# SAMA7D65D2GN8 register map
Vendor: Microchip Technology; Series: SAMA7D6; File version: 0
Registers are 32-bit, read-write, reset 0x0 unless marked. A register's access mark holds for its fields unless they carry their own. Offsets are from the block's base; [hi:lo] are bit positions; lines under a group give offsets from that group; {n}, {i} and the like mark numbered series; 'fields as' and 'values as' point back to an identical list.

## I2SMCC0 — Inter-IC Sound Multi Channel Controller
Base 0xE2814000; register names take the prefix I2SMCC_
Same registers: I2SMCC1 0xE2818000
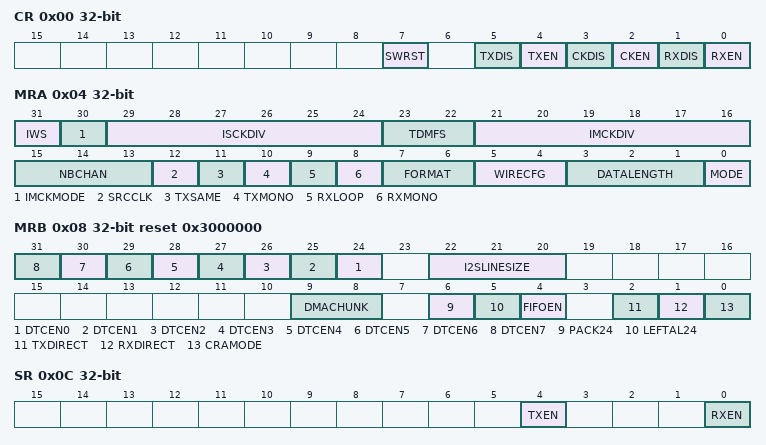
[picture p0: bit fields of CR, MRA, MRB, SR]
0x00 CR wo — Control Register
  [7] SWRST — Software Reset
    0=No effect; 1=Resets all the registers in the I2SMCC. The I2SMCC is disabled after the reset.
  [5] TXDIS — Transmitter Disable
    0=No effect; 1=Disables the I2SMCC transmitter. Bit I2SMCC_SR.TXEN is cleared when the Transmitter is stopped.
  [4] TXEN — Transmitter Enable
    0=No effect; 1=Enables the I2SMCC transmitter, if TXDIS is not '1'. Bit I2SMCC_SR.TXEN is set when the Transmitter is started.
  [3] CKDIS — Clocks Disable
    0=No effect; 1=Disables the I2SMCC clock generation
  [2] CKEN — Clocks Enable
    0=No effect; 1=Enables the I2SMCC clock generation, if CKDIS is not '1'
  [1] RXDIS — Receiver Disable
    0=No effect; 1=Disables the I2SMCC receiver. Bit I2SMCC_SR.RXEN is cleared when the receiver is stopped.
  [0] RXEN — Receiver Enable
    0=No effect; 1=Enables the I2SMCC receiver, if RXDIS is not '1'. Bit I2SMCC_SR.RXEN is set when the receiver is activated.
0x04 MRA — Mode Register A
  [31] IWS — I2SMCC_WS Slot Length
    0=I2SMCC_WS slot is 32 bits long for DATALENGTH = 18/20/24 bits; 1=I2SMCC_WS slot is 24 bits long for DATALENGTH = 18/20/24 bits
  [30] IMCKMODE — Host Clock Mode
    0=No host clock generated; 1=Host clock generated
  [29:24] ISCKDIV — Selected Clock to I2SMCC Serial Clock Ratio
  [23:22] TDMFS — TDM Frame Synchronization
    0=SLOT (I2SMCC_WS pulse is high for one time slot at beginning of frame.); 1=HALF (I2SMCC_WS pulse is high for half the time slots at beginning of frame.); 2=BIT (I2SMCC_WS pulse is high for one bit period at beginning of frame, i.e., one I2SMCC_CK period.)
  [21:16] IMCKDIV — Selected Clock to I2SMCC Host Clock Ratio
  [15:13] NBCHAN — Number of TDM Channels-1
  [12] SRCCLK — Source Clock Selection
    0=The Peripheral clock is selected as source clock for I2SMCC_MCK/WS/CK pins; 1=The PMC.GCLKx clock is selected as source clock (I2SMCC_MCK/WS/CK rate can be independent of system bus clock)
  [11] TXSAME — Transmit Data when Underrun
    0='0' is transmitted when underrun; 1=Previous sample transmitted when underrun
  [10] TXMONO — Transmit Mono
    0=Stereo; 1=Mono, with left audio samples duplicated to right audio channel by the I2SMCC
  [9] RXLOOP — Loop-back Test Mode
    0=Normal mode; 1=I2SMCC_DOUT outputs of I2SMCC are internally connected to I2SMCC_DIN inputs
  [8] RXMONO — Receive Mono
    values as TXMONO
  [7:6] FORMAT — Data Format
    0=I2S (I2S format, stereo with I2SMCC_WS low for left channel, and MSB of sample starting one I2SMCC_CK period after I2SMCC_WS edge.); 1=LJ (Left-justified format, stereo with I2SMCC_WS high for left channel, and MSB of sample starting on I2SMCC_WS edge.); 2=TDM (TDM format, with (NBCHAN + 1) channels, I2SMCC_WS high at beginning of first channel, and MSB of sample starting one I2SMCC_CK period after I2SMCC_WS edge.); 3=TDMLJ (TDM format, left-justified, with (NBCHAN + 1) channels, I2SMCC_WS high at beginning of first channel, and MSB of sample starting on I2SMCC_WS edge.)
  [5:4] WIRECFG — Wire Configuration
    0=I2S_1_TDM_0 (In I2S and LJ formats, I2SMCC_DIN0 and I2SMCC_DOUT0 are used to transmit and receive I2S frames. In TDM and TDMLJ formats, I2SMCC_DIN0 and I2SMCC_DOUT0 are used to transmit and receive TDM frames.); 1=I2S_2_TDM_1 (In I2S and LJ formats, I2SMCC_DIN[1:0] and I2SMCC_DOUT[1:0] are used to transmit and receive 2 I2S frames. In TDM and TDMLJ formats, I2SMCC_DIN1 and I2SMCC_DOUT1 are used to transmit and receive TDM frames.); 2=I2S_4_TDM_2 (In I2S and LJ formats, I2SMCC_DIN[3:0] and I2SMCC_DOUT[3:0] are used to transmit and receive 4 I2S frames. In TDM and TDMLJ formats, I2SMCC_DIN2 and I2SMCC_DOUT2 are used to transmit and receive TDM frames.); 3=TDM_3 (In I2S and LJ formats, reserved for future use, do not use. In TDM and TDMLJ formats, I2SMCC_DIN3 and I2SMCC_DOUT3 are used to transmit and receive TDM frames.)
  [3:1] DATALENGTH — Data Word Length
    0=32_BITS (Data length is set to 32 bits.); 1=24_BITS (Data length is set to 24 bits.); 2=20_BITS (Data length is set to 20 bits.); 3=18_BITS (Data length is set to 18 bits.); 4=16_BITS (Data length is set to 16 bits.); 5=16_BITS_COMPACT (Data length is set to 16-bit compact stereo. Left sample in bits [15:0] and right sample in bits [31:16] of same word.); 6=8_BITS (Data length is set to 8 bits.); 7=8_BITS_COMPACT (Data length is set to 8-bit compact stereo. Left sample in bits [7:0] and right sample in bits [15:8] of the same word.)
  [0] MODE — Inter-IC Sound Multi Channel Controller Mode
    0=SLAVE (Client mode. I2SMCC_CK and I2SMCC_WS pin inputs used as bit clock and word select/frame synchronization.); 1=MASTER (Host mode. Bit clock and word select/frame synchronization generated by I2SMCC from Peripheral Clock or GCLK if I2SMCC_MCK/WS/CK rates must be independent of system bus clock (See I2SMCC_MR.SRCCLK) and output to I2SMCC_CK and I2SMCC_WS pins. MCK is output as host clock on I2SMCC_MCK if I2SMCC_MRA.IMCKMODE is set.)
0x08 MRB reset 0x3000000 — Mode Register B
  [n+24] DTCEN{n} (n=0..7) — Direct Audio Transmit Channel {n} Enable
    0=The channel x from the direct audio stream is not transmitted on I2S line; 1=The channel x from the direct audio stream is transmitted on I2S line
  [22:20] I2SLINESIZE — I2S Transceiver Data Slot Size Selection
    0=DATALENGTH_DEFINED (The I2S data slot size is configured by I2SMCC_MRA.DATALENGTH and the software is forced to manage audio samples of the same size as the ones transfered on I2S line.); 1=32_BITS (The I2S data slot size is 32-bit. I2SMCC_MRA.DATALENGTH/IWS has no effect on I2S data slot size but defines the audio sample size managed at user interface level.); 2=32_24_BITS (The I2S data slot size is 24-bit or 32-bit. 32 or 24 bits depends on I2SMCC_MR.IWS. I2SMCC_MRA.DATALENGTH/IWS have no effect on I2S data slot size but define the audio sample size managed at user interface level.); 3=16_BITS (The I2S data slot size is 16-bit. I2SMCC_MRA.DATALENGTH/IWS have no effect on I2S data slot size but defines the audio sample size managed at user interface level.); 4=8_BITS (The I2S data slot size is 8-bit. I2SMCC_MRA.DATALENGTH/IWS have no effect on I2S data slot size but defines the audio sample size managed at user interface level.)
  [9:8] DMACHUNK — DMA Chunk Size
    0=1_WORD (A DMA transfer request is issued when at least 1 word is empty in the FIFO.); 1=2_WORDS (A DMA transfer request is issued when at least 2 words are empty in the FIFO. When PACK24=1, only 1-word chunks are allowed for the DMA transfer.); 2=4_WORDS (A DMA transfer request is issued when at least 4 words are empty in the FIFO. Limitations exist when operating in Mono or TDM. See Table 7-7 'TX DMA Chunk Configurations' and Table 7-8 'RX DMA Chunk Configurations'. When PACK24=1, only 1-word chunks are allowed for the DMA transfer.); 3=8_WORDS (A DMA transfer request is issued when at least 8 words are empty in the FIFO. Limitations exist when operating in Mono or TDM. See Table 7-7 'TX DMA Chunk Configurations' and Table 7-8 'RX DMA Chunk Configurations'. When PACK24=1, only 1-word chunks are allowed for the DMA transfer.)
  [6] PACK24 — Packed 24-bit Mode
    0=Each 24-bit audio sample is mapped into the 32-bit Holding register; 1=24-bit audio samples are compacted in the 32-bit Holding register to optimize data transfer in system bus and memory. The FIFO must be enabled (I2SMCC_MRB.FIFOEN = 1).
  [5] LEFTAL24 — Left Aligned 24-bit Data
    0=The 24-bit audio sample is right aligned in the 32-bit Holding register; 1=The 24-bit audio sample is left aligned in the 32-bit Holding register
  [4] FIFOEN — FIFO Enable
    0=The Receive and Transmit FIFOs are disabled; 1=The Receive and Transmit FIFOs are enabled. Transmit data can only be written through I2SMCC_THR. Receive data can only be read through I2SMCC_RHR.
  [2] TXDIRECT — Transmitter Direct Access Enable
    0=The I2SMCC_THR must be loaded by software or DMA to transfer audio sample on I2S line; 1=Audio Sample Rate Converter (ASRC) can directly transmit the converted audio samples on I2S line without software or DMA intervention. The FIFO must be enabled (I2SMCC_MRB.FIFOEN = 1).
  [1] RXDIRECT — Receiver Direct Access Enable
    0=The I2SMCC_RHR must be read by software or DMA to read audio samples from I2S line; 1=Audio Sample Rate Converter (ASRC) can be directly loaded with the audio samples recovered from I2S line without software or DMA intervention. The FIFO must be enabled (I2SMCC_MRB.FIFOEN = 1).
  [0] CRAMODE — Common Register Access Mode
    0=LEFT_FIRST (All enabled I2S left channels are filled first, then I2S right channels.); 1=REGULAR (An enabled I2S left channel is filled, then the corresponding right channel, until all channels are filled.)
0x0C SR ro — Status Register
  [4] TXEN — Transmitter Enabled
    0=Cleared when the transmitter is disabled, following a I2SMCC_CR.TXDIS or I2SMCC_CR.SWRST request; 1=Set when the transmitter is enabled, following a I2SMCC_CR.TXEN request
  [0] RXEN — Receiver Enabled
    0=Cleared when the receiver is disabled, following a RXDIS or SWRST request in I2SMCC_CR; 1=Set when the receiver is enabled, following a RXEN request in I2SMCC_CR
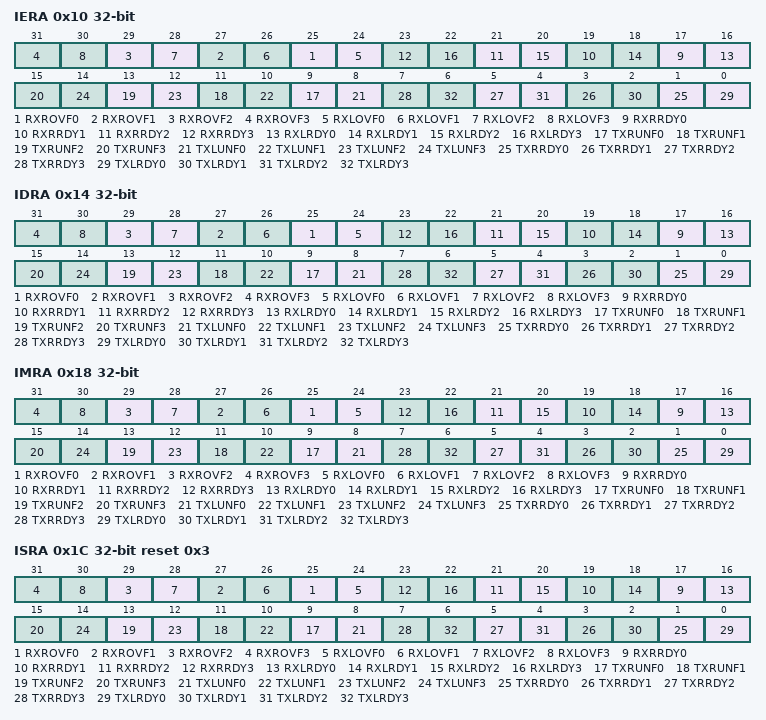
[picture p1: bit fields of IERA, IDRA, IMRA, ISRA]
0x10 IERA wo — Interrupt Enable Register A
  [2n+25] RXROVF{n} (n=0..3) — I2S Receive Right {n} or TDM Channel [2x]+1 Overrun Interrupt Enable
  [2n+24] RXLOVF{n} (n=0..3) — I2S Receive Left {n} or TDM Channel 2x Overrun Interrupt Enable
  [2n+17] RXRRDY{n} (n=0..3) — I2S Receive Right {n} or TDM Channel [2x]+1 Ready Interrupt Enable
  [2n+16] RXLRDY{n} (n=0..3) — I2S Receive Left {n} or TDM Channel 2x Ready Interrupt Enable
  [2n+9] TXRUNF{n} (n=0..3) — I2S Transmit Right {n} or TDM Channel [2x]+1 Underrun Interrupt Enable
  [2n+8] TXLUNF{n} (n=0..3) — I2S Transmit Left {n} or TDM Channel 2x Underrun Interrupt Enable
  [2n+1] TXRRDY{n} (n=0..3) — I2S Transmit Right {n} or TDM Channel [2x]+1 Ready Interrupt Enable
  [2n] TXLRDY{n} (n=0..3) — I2S Transmit Left {n} or TDM Channel 2x ReadyInterrupt Enable
0x14 IDRA wo — Interrupt Disable Register A
  [2n+25] RXROVF{n} (n=0..3) — I2S Receive Right {n} or TDM Channel [2x]+1 Overrun Interrupt Disable
  [2n+24] RXLOVF{n} (n=0..3) — I2S Receive Left {n} or TDM Channel 2x Overrun Interrupt Disable
  [2n+17] RXRRDY{n} (n=0..3) — I2S Receive Right {n} or TDM Channel [2x]+1 Ready Interrupt Disable
  [2n+16] RXLRDY{n} (n=0..3) — I2S Receive Left {n} or TDM Channel 2x Ready Interrupt Disable
  [2n+9] TXRUNF{n} (n=0..3) — I2S Transmit Right {n} or TDM Channel [2x]+1 Underrun Interrupt Disable
  [2n+8] TXLUNF{n} (n=0..3) — I2S Transmit Left {n} or TDM Channel 2x Underrun Interrupt Disable
  [2n+1] TXRRDY{n} (n=0..3) — I2S Transmit Right {n} or TDM Channel [2x]+1 Ready Interrupt Disable
  [2n] TXLRDY{n} (n=0..3) — I2S Transmit Left {n} or TDM Channel 2x ReadyInterrupt Disable
0x18 IMRA ro — Interrupt Mask Register A
  [2n+25] RXROVF{n} (n=0..3) — I2S Receive Right {n} or TDM Channel [2x]+1 Overrun Interrupt Mask
  [2n+24] RXLOVF{n} (n=0..3) — I2S Receive Left {n} or TDM Channel 2x Overrun Interrupt Mask
  [2n+17] RXRRDY{n} (n=0..3) — I2S Receive Right {n} or TDM Channel [2x]+1 Ready Interrupt Mask
  [2n+16] RXLRDY{n} (n=0..3) — I2S Receive Left {n} or TDM Channel 2x Ready Interrupt Mask
  [2n+9] TXRUNF{n} (n=0..3) — I2S Transmit Right {n} or TDM Channel [2x]+1 Underrun Interrupt Mask
  [2n+8] TXLUNF{n} (n=0..3) — I2S Transmit Left {n} or TDM Channel 2x Underrun Interrupt Mask
  [2n+1] TXRRDY{n} (n=0..3) — I2S Transmit Right {n} or TDM Channel [2x]+1 Ready Interrupt Mask
  [2n] TXLRDY{n} (n=0..3) — I2S Transmit Left {n} or TDM Channel 2x ReadyInterrupt Mask
0x1C ISRA ro reset 0x3 — Interrupt Status Register A
  [2n+25] RXROVF{n} (n=0..3) — I2S Receive Right {n} or TDM Channel [2x]+1 Overrun Flag (Cleared on read)
    0=Cleared when I2SMCC_ISRA is read; 1=Set when an overrun error occurs in either I2SMCC_RHRxR or I2SMCC_RHR
  [2n+24] RXLOVF{n} (n=0..3) — I2S Receive Left {n} or TDM Channel 2x Overrun Flag (Cleared on read)
    0=Cleared when I2SMCC_ISRA is read; 1=Set when an overrun error occurs in either I2SMCC_RHLxR or I2SMCC_RHR
  [2n+17] RXRRDY{n} (n=0..3) — I2S Receive Right {n} or TDM Channel [2x]+1 Ready Flag (Cleared by reading I2SMCC_RHR/RHLxR)
    0=Cleared when a predefined number of read accesses is performed in I2SMCC_RHRxR or I2SMCC_RHR. The predefined number depends on the configuration of I2SMCC_MRA.WIRECFG / FORMAT and varies from 1 to 8.; 1=Set when received data is available in either I2SMCC_RHRxR or I2SMCC_RHR
  [2n+16] RXLRDY{n} (n=0..3) — I2S Receive Left {n} or TDM Channel 2x Ready Flag (Cleared by reading I2SMCC_RHR/RHLxR)
    0=Cleared when a predefined number of read accesses are performed in either I2SMCC_RHLxR or I2SMCC_RHR. The predefined number depends on the configuration of I2SMCC_MRA.WIRECFG / FORMAT and varies from 1 to 7.; 1=Set when received data is available in either I2SMCC_RHLxR or I2SMCC_RHR
  [2n+9] TXRUNF{n} (n=0..3) — I2S Transmit Right {n} or TDM Channel [2x]+1 Underrun Flag (Cleared on read)
    0=Cleared when the I2SMCC_ISRA is read; 1=Set when an underrun error occurs in either I2SMCC_THR or I2SMCC_THRxR
  [2n+8] TXLUNF{n} (n=0..3) — I2S Transmit Left {n} or TDM Channel 2x Underrun (Cleared on read)
    0=Cleared when I2SMCC_ISRA is read; 1=Set when an underrun error occurs in either I2SMCC_THR or I2SMCC_THLxR
  [2n+1] TXRRDY{n} (n=0..3) — I2S Transmit Right {n} or TDM Channel [2x]+1 Ready Flag (Cleared by writing I2SMCC_THR/THRxR)
    0=Cleared when a predefined number of write accesses are performed in either I2SMCC_THRxR or I2SMCC_THR. The predefined number depends on the configuration of I2SMCC_MRA.WIRECFG / FORMAT and varies from 1 to 8.; 1=Set when I2SMCC_THR or I2SMCC_THRxR is empty
  [2n] TXLRDY{n} (n=0..3) — I2S Transmit Left {n} or TDM Channel 2x Ready Flag (Cleared by writing I2SMCC_THR/THLxR)
    0=Cleared when a predefined number of write accesses are performed in either I2SMCC_THLxR or I2SMCC_THR. The predefined number depends on the configuration of I2SMCC_MRA.WIRECFG / FORMAT and varies from 1 to 7.; 1=Set when I2SMCC_THR or I2SMCC_THLxR is empty
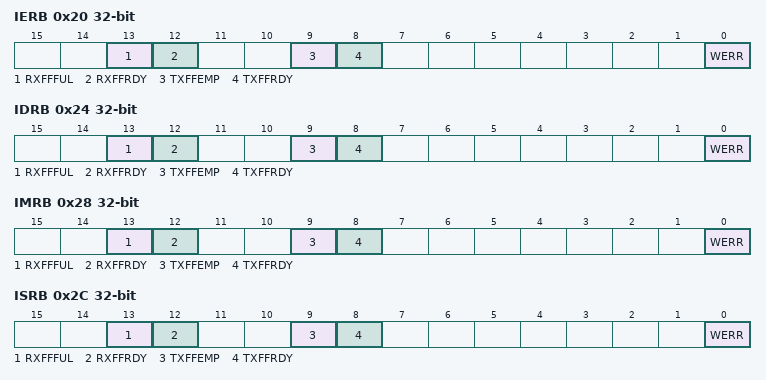
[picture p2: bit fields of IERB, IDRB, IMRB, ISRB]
0x20 IERB wo — Interrupt Enable Register B
  [13] RXFFFUL — RX FIFO Full Interrupt Enable
  [12] RXFFRDY — RX FIFO Ready Interrupt Enable
  [9] TXFFEMP — TX FIFO Empty Interrupt Enable
  [8] TXFFRDY — TX FIFO Ready Interrupt Enable
  [0] WERR — Write Error Interrupt Enable
0x24 IDRB wo — Interrupt Disable Register B
  [13] RXFFFUL — RTX FIFO Full Interrupt Disable
  [12] RXFFRDY — RX FIFO Ready Interrupt Disable
  [9] TXFFEMP — TX FIFO Empty Interrupt Disable
  [8] TXFFRDY — TX FIFO Ready Interrupt Disable
  [0] WERR — Write Error Interrupt Disable
0x28 IMRB ro — Interrupt Mask Register B
  [13] RXFFFUL — RX FIFO Full Interrupt Mask
  [12] RXFFRDY — RX FIFO Ready Interrupt Mask
  [9] TXFFEMP — TX FIFO Empty Interrupt Mask
  [8] TXFFRDY — TX FIFO Ready Interrupt Mask
  [0] WERR — Write Error Interrupt Enable
0x2C ISRB ro — Interrupt Status Register B
  [13] RXFFFUL — RX FIFO Full Flag (Cleared on read)
    0=Cleared when I2SMCC_ISRB is read; 1=Set when RX FIFO is full and I2SMCC_MRB.FIFOEN = 1
  [12] RXFFRDY — RX FIFO Ready Flag (Cleared on read)
    0=Cleared when I2SMCC_ISRB is read; 1=Set when RX FIFO is ready to be read and I2SMCC_MRB.FIFOEN = 1
  [9] TXFFEMP — TX FIFO Empty Flag (Cleared on read)
    0=Cleared when I2SMCC_ISRB is read; 1=Set when TX FIFO is empty and I2SMCC_MRB.FIFOEN = 1
  [8] TXFFRDY — TX FIFO Ready Flag (Cleared on read)
    0=Cleared when I2SMCC_ISRB is read; 1=Set when TX FIFO is ready to be written and I2SMCC_MRB.FIFOEN = 1
  [0] WERR — Write Error or Security Error Flag (cleared on read)
    0=Cleared when I2SMCC_ISRB is read; 1=Set when an error occurs in the I2SMCC_WPSR. Refer to I2SMCC_WPSR for details on the type of error.
0x30 RHR ro — Receiver Holding Register
0x34 THR wo — Transmitter Holding Register
{0x40+8i} I2SMCC_RH[{i}] (i=0..3) group
  0x00 RHLxR ro — Receiver Holding Left x Register
    [31:0] RHL — Receiver Holding Left
  0x04 RHRxR ro — Receiver Holding Right x Register
    [31:0] RHR — Receiver Holding Right
{0x60+8i} I2SMCC_TH[{i}] (i=0..3) group
  0x00 THLxR wo — Transmitter Holding Left x Register
    [31:0] THL — Transmitter Holding Left
  0x04 THRxR wo — Transmitter Holding Right x Register
    [31:0] THR — Transmitter Holding Right
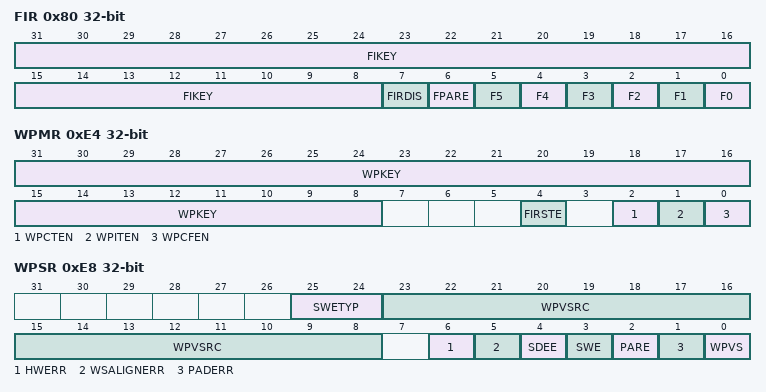
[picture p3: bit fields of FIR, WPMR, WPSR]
0x80 FIR — Fault Injection Register
  [31:8] FIKEY — Fault Injection Access Key
    0x494649=PASSWD (Writing any other value in this field aborts the write operation.)
  [7] FIRDIS — Fault Injection Register Disable
    0=NO_EFFECT; 1=ACTIVE (Disables the fault injection until the next hardware reset. The command is valid only if the I2SMCC_WPSR.PARE=0 and the other bits are cleared (F0=F1=F2=F3=F4=FPARE=0).)
  [6] FPARE — Single Fault for I2SMCC Configuration Register
    0=NO_EFFECT; 1=INJECT (Injects a single fault on configuration register if the I2SMCC receiver and transmitter are both disabled (for security reasons), the flag I2SMCC_WPSR.PARE rises and the flag I2SMCC_ISRB.WERR =1. To clear the fault, all the fields of the corresponding Configuration registers must be reconfigured. For I2SMCC_IMR, the clear is performed by writing a '1' into all the fields of I2SMCC_IDR. Thus the functional value must be reloaded by writing in I2SMCC_IER.)
  [5] F5 — Single Fault for I2SMCC Write Protection Enable bit (I2SMCC_WPMR.WPCFEN)
    0=Clears the fault; 1=Injects a single fault I2SMCC_CR.WPCFEN if 0x494649 ('IFI' in ASCII) is written in the FIKEY field at the same time and if the flag I2SMCC_FIR.FIRDIS=0. The I2SMCC remains in the same state, the flag I2SMCC_ISRB.WERR=1 and the flag I2SMCC_WPSR.SDEE=1.
  [4] F4 — Single Fault for I2SMCC Transmitter Direct Access Enable bit (I2SMCC_CR.TXDIRECT)
    0=Clears the fault; 1=Injects a single fault I2SMCC_CR.TXDIRECT if 0x494649 ('IFI' in ASCII) is written in the FIKEY field at the same time and if the flag I2SMCC_FIR.FIRDIS=0. The I2SMCC remains in the same state, the flag I2SMCC_ISRB.WERR=1 and the flag I2SMCC_WPSR.SDEE=1.
  [3] F3 — Single Fault for I2SMCC Receiver Direct Access Enable bit (I2SMCC_CR.RXDIRECT)
    0=Clears the fault; 1=Injects a single fault I2SMCC_CR.RXDIRECT if 0x494649 ('IFI' in ASCIIis written in the FIKEY field at the same time and if the flag I2SMCC_FIR.FIRDIS=0. The I2SMCC remains in the same state, the flag I2SMCC_ISRB.WERR=1 and the flag I2SMCC_WPSR.SDEE=1.
  [2] F2 — Single Fault for I2SMCC Transmitter Enable bit (I2SMCC_CR.TXEN/TXDIS)
    0=Clears the fault; 1=Injects a single fault I2SMCC_CR.TXEN/TXDIS if 0x494649 ('IFI' in ASCII) is written in the FIKEY field at the same time and if the flag I2SMCC_FIR.FIRDIS=0. The I2SMCC remains in the same state, the flag I2SMCC_ISRB.WERR=1 and the flag I2SMCC_WPSR.SDEE=1.
  [1] F1 — Single Fault for I2SMCC Clock Enable bit (I2SMCC_CR.CLKEN/CLKDIS)
    0=Clears the fault; 1=Injects a single fault on I2SMCC_CR.CLKEN/CLKDIS if 0x494649 ('IFI' in ASCII) is written in the FIKEY field at the same time and if the flag I2SMCC_FIR.FIRDIS=0. The I2SMCC remains in the same state, the flag I2SMCC_ISRB.WERR=1 and the flag I2SMCC_WPSR.SDEE=1.
  [0] F0 — Single Fault for I2SMCC Receiver Enable bit (I2SMCC_CR.RXEN/RXDIS)
    0=Clears the fault; 1=Injects a single fault on I2SMCC_CR.RXEN/RXDIS if 0x494649 ('IFI' in ASCII) is written in the FIKEY field at the same time and if the flag I2SMCC_FIR.FIRDIS=0. The I2SMCC remains in the same state, the flag I2SMCC_ISRB.WERR=1 and the flag I2SMCC_WPSR.SDEE=1.
0xE4 WPMR — Write Protection Mode Register
  [31:8] WPKEY — Write Protection Key
    0x493253=PASSWD (Writing any other value in this field aborts the write operation. Always reads as 0.)
  [4] FIRSTE — First Error Report Enable
    0=The last write protection violation source is reported in I2SMCC_WPSR.WPVSRC and the last software control error type is reported in I2SMCC_WPSR.SWETYP. The I2SMCC_ISRB.WERR flag is set at the first error occurrence within a series.; 1=Only the first write protection violation source is reported in I2SMCC_WPSR.WPVSRC and only the first software control error type is reported in I2SMCC_WPSR.SWETYP. The I2SMCC_ISRB.WERR flag is set at the first error occurrence within a series.
  [2] WPCTEN — Write Protection Control Enable
    0=Disables the write protection of the control if WPKEY matches to 0x493253 (I2S in ASCII); 1=Enables the write protection of the control if WPKEY matches to 0x493253 (I2S in ASCII)
  [1] WPITEN — Write Protection Interrupt Enable
    0=Disables the write protection of the interruption if WPKEY matches to 0x493253 (I2S in ASCII); 1=Enables the write protection of the interruption if WPKEY matches to 0x493253 (I2S in ASCII)
  [0] WPCFEN — Write Protection Configuration Enable
    0=Disables the write protection of the configuration if WPKEY matches to 0x493253 (I2S in ASCII); 1=Enables the write protection of the configuration if WPKEY matches to 0x493253 (I2S in ASCII)
0xE8 WPSR ro — Write Protection Status Register
  [25:24] SWETYP — Software Error Type (cleared on read)
    0=READ_WO (A write-only register has been read.); 1=WRITE_RO (A write access has been performed on a read-only register.); 2=UNDEF_RW (Access to an undefined address.)
  [23:8] WPVSRC — Write Protection Violation Source
  [6] HWERR — Hardware Error in Client Mode and Direct Access Transfer
    0=No abnormal underflow in transmitter detected In Client mode and direct access with ASRC; 1=Abnormal underflow detected in transmitter when configured in Client mode and direct access with ASRC. The transmitter is automatically re-initialized to continue streaming the audio samples from ASRC. The error may be created from an unexpected disable of the direct access mode in ASRC or from an abnormal condition on the I2SMCC_CK/WS pins.
  [5] WSALIGNERR — WS Alignment Error (cleared on read)
    0=No internal nonalignment that could result from abnormal conditions on I2SMCC_WS/CK input pins; 1=In Client mode (I2SMCC_WS/CK are inputs), an abnormal alignment has been detected between internal WS and CK signals. This may result from a glitch on I2SMCC_CK or I2SMCC_WS drivers or the absence of voltage hysteresis management on the pad buffer driving the internal CK clock pin. This flag may also be asserted when the audio codec providing WS/CK generates an unexpected misalignment.
  [4] SDEE — Single or Dual Event Error (cleared by reconfiguring the faulty registers or by clearing the error via I2SMCC_FIR)
    0=No single or dual error detected in I2SMCC_CR.RXEN/RXDIS, I2SMCC_CR.TXEN/TXDIS, I2SMCC_CR.CLKEN/CLKDIS, I2SMCC_MRB.RXDIRECT/TXDIRECT, I2SMCC_WPMR.WPCFEN, I2SMCC_WPMR.WPITEN, I2SMCC_WPMR.WPCTEN bits; 1=Single or dual error detected in I2SMCC_MRA.I2SMCC_CR.RXEN/RXDIS, I2SMCC_CR.TXEN/TXDIS, I2SMCC_CR.CLKEN/CLKDIS, I2SMCC_MRB.RXDIRECT/TXDIRECT, I2SMCC_WPMR.WPCFEN, I2SMCC_WPMR.WPITEN, I2SMCC_WPMR.WPCTEN bits
  [3] SWE — Software Control Error (cleared on read)
    0=No software error has occurred since the last read of I2SMCC_WPSR; 1=A software error has occurred since the last read of I2SMCC_WPSR. The field SWETYP details the type of software error; the associated incorrect software access is reported in the field WPVSRC (if WPVS=0).
  [2] PARE — Internal Single Error Detection Configuration Registers
    0=No internal single error has been detected on configuration registers since the last read of I2SMCC_WPSR; 1=An internal single error has been detected. This flag is set under abnormal operating conditions or if the fault injection I2SMCC_FIR.FPARE is performed (only available if I2SMCC RX and TX are both disabled). I2SMCC_MRA/MRB/IMRA/IMRB and WPMR registers are monitored with a single error detection for each register.
  [1] PADERR — WS or CK Pad Error (cleared on read)
    0=No error has been detected on I2SMCC_WS and I2SMCC_CK pad outputs since the last read of I2SMCC_WPSR; 1=Two successive erroneous samplings of WS pad output or abnormal number of clock edges have been detected on I2SMCC_CK pad output during the transmission of 1 audio sample. The event occurred since the last read of I2SMCC_WPSR.
  [0] WPVS — Write Protection Violation Status (cleared on read)
    0=No write protection violation has occurred since the last read of the I2SMCC_WPSR; 1=A write protection violation has occurred since the last read of the I2SMCC_WPSR. If this violation is an unauthorized attempt to write a protected register, the associated violation is reported into field WPVSRC.
